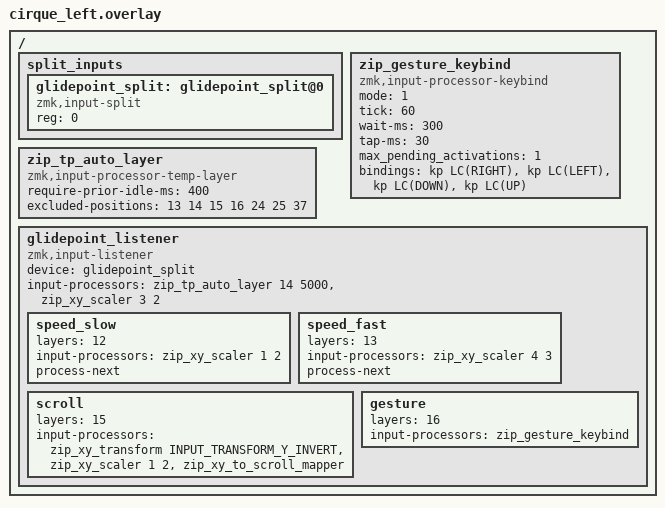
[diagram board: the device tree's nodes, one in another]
/*
 * Lado central (izquierda): recibe los eventos del trackpad Cirque del
 * periférico vía input-split y los procesa con el listener. Nodos propios
 * del shield (los shields se procesan antes que el keymap).
 */

#include <input/processors.dtsi>
#include <dt-bindings/zmk/input_transform.h>
#include <dt-bindings/zmk/keys.h>

/ {
    split_inputs {
        #address-cells = <1>;
        #size-cells = <0>;

        glidepoint_split: glidepoint_split@0 {
            compatible = "zmk,input-split";
            reg = <0>;
        };
    };

    /* Modo gesto (capa fantasma 16): cuantiza el movimiento del pad en
     * atajos de Mission Control. Orden de bindings del driver:
     * RIGHT, LEFT, DOWN, UP. Swipe → = ir al escritorio de la derecha
     * (Ctrl+→); si se prefiere "el contenido sigue al dedo" (como el swipe
     * nativo de 3 dedos), intercambiar los dos primeros bindings. */
    zip_gesture_keybind: zip_gesture_keybind {
        compatible = "zmk,input-processor-keybind";
        #input-processor-cells = <0>;
        mode = <1>;       /* 4-way: domina el eje con más movimiento */
        tick = <60>;      /* unidades de delta por activación: swipe amplio */
        wait-ms = <300>;  /* pausa entre activaciones — evita ráfagas */
        tap-ms = <30>;
        max_pending_activations = <1>; /* 1 gesto por swipe, sin cola */
        bindings = <&kp LC(RIGHT)>, <&kp LC(LEFT)>, <&kp LC(DOWN)>, <&kp LC(UP)>;
    };

    /* Auto mouse layer: mover el pad activa temporalmente la capa Trackpad
     * (L14) — clicks en A/R/S disponibles sin sostener REPT.
     *  - Ventana de 5s tras el último movimiento (3s resultó corto en uso
     *    real): da tiempo a apuntar,
     *    seleccionar y hacer click derecho sin apurarse. Salida anticipada:
     *    tecla EXIT en T (&tog_off 14 — el processor detecta el cambio de
     *    capa externo y cancela su timer) o cualquier tecla no excluida.
     *  - require-prior-idle-ms: no se activa si se tipeó hace <400ms.
     *  - excluded-positions: teclas de la capa que NO la desactivan
     *    (A/R/S clicks, T exit, REPT, Z scroll, pulgar GEST); cualquier
     *    otra tecla la corta y tipea normal. Q/W/F (selector x1/x2/x3)
     *    NO están excluidas a propósito: tipearlas en la ventana debe
     *    tipear la letra, no cambiar la velocidad en silencio — el
     *    selector se usa con la capa sostenida (hold REPT), donde este
     *    processor no interfiere (solo desactiva capas que él activó).
     * Tradeoff conocido: tipear A/R/S/T/Z dentro de la ventana
     * post-movimiento ejecuta el panel en vez de la letra — si molesta,
     * bajar el timeout (2º param) o quitar este processor de la cadena. */
    zip_tp_auto_layer: zip_tp_auto_layer {
        compatible = "zmk,input-processor-temp-layer";
        #input-processor-cells = <2>;
        require-prior-idle-ms = <400>;
        excluded-positions = <13 14 15 16 24 25 37>;
    };

    glidepoint_listener: glidepoint_listener {
        compatible = "zmk,input-listener";
        device = <&glidepoint_split>;
        /* x1.5 por software sobre la ganancia 3x del sensor (su máximo
         * usable). Subir/bajar velocidad = cambiar esta fracción.
         * zip_tp_auto_layer primero: cada evento del pad (re)activa L14
         * por 5s. */
        input-processors = <&zip_tp_auto_layer 14 5000>, <&zip_xy_scaler 3 2>;

        /* Selector x1/x2/x3 (capas fantasma 12/13 del keymap, radio-button
         * desde la capa Mouse). x2 = default (solo el escalador base). */
        speed_slow {
            layers = <12>;
            input-processors = <&zip_xy_scaler 1 2>; /* x1: net 0.75 */
            process-next;
        };
        speed_fast {
            layers = <13>;
            input-processors = <&zip_xy_scaler 4 3>; /* x3: net 2.0 */
            process-next;
        };

        /* Modo scroll (capa fantasma 15, hold SCRL en Trackpad L14): los
         * deltas X/Y se convierten en rueda. Sin process-next: al scrollear
         * no se aplica el escalador base del cursor.
         *  - Y_INVERT = scroll natural (contenido sigue al dedo); si queda
         *    al revés, borrar esa transform.
         *  - 1/2 con SMOOTH_SCROLLING (multiplicador HID 16: el host divide
         *    la rueda por 16) — neto 1/32 de línea por unidad de delta. El
         *    2/1 inicial resultó demasiado rápido en uso real; ajustar esta
         *    fracción para acelerar/frenar (track-remainders acumula los
         *    restos, el scroll lento no pierde movimiento). */
        scroll {
            layers = <15>;
            input-processors
                = <&zip_xy_transform INPUT_TRANSFORM_Y_INVERT>
                , <&zip_xy_scaler 1 2>
                , <&zip_xy_to_scroll_mapper>;
        };

        /* Modo gesto (capa fantasma 16, hold GEST en Trackpad L14): el pad
         * deja de mover el cursor y cada swipe dispara un atajo de Mission
         * Control / escritorios. Sin process-next. */
        gesture {
            layers = <16>;
            input-processors = <&zip_gesture_keybind>;
        };
    };
};
